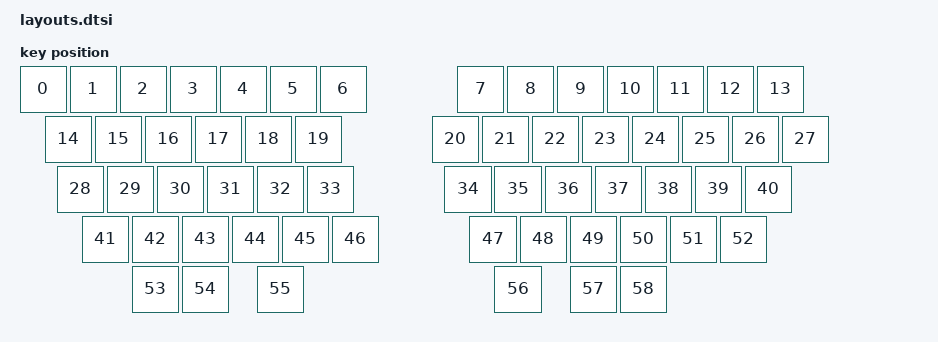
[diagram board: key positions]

#include <physical_layouts.dtsi>
/ {
    physical_layout0: physical_layout0 {
        compatible = "zmk,physical-layout";
        display-name = "Layout";
        keys
            = <&key_physical_attrs 100 100 (-50) 0 0 0 0>
			,<&key_physical_attrs 100 100 50 0 0 0 0>
			,<&key_physical_attrs 100 100 150 0 0 0 0>
			,<&key_physical_attrs 100 100 250 0 0 0 0>
			,<&key_physical_attrs 100 100 350 0 0 0 0>
			,<&key_physical_attrs 100 100 450 0 0 0 0>
			,<&key_physical_attrs 100 100 550 0 0 0 0>
			,<&key_physical_attrs 100 100 825 0 0 0 0>
			,<&key_physical_attrs 100 100 925 0 0 0 0>
			,<&key_physical_attrs 100 100 1025 0 0 0 0>
			,<&key_physical_attrs 100 100 1125 0 0 0 0>
			,<&key_physical_attrs 100 100 1225 0 0 0 0>
			,<&key_physical_attrs 100 100 1325 0 0 0 0>
			,<&key_physical_attrs 100 100 1425 0 0 0 0>
			,<&key_physical_attrs 100 100 0 100 0 0 0>
			,<&key_physical_attrs 100 100 100 100 0 0 0>
			,<&key_physical_attrs 100 100 200 100 0 0 0>
			,<&key_physical_attrs 100 100 300 100 0 0 0>
			,<&key_physical_attrs 100 100 400 100 0 0 0>
			,<&key_physical_attrs 100 100 500 100 0 0 0>
			,<&key_physical_attrs 100 100 775 100 0 0 0>
			,<&key_physical_attrs 100 100 875 100 0 0 0>
			,<&key_physical_attrs 100 100 975 100 0 0 0>
			,<&key_physical_attrs 100 100 1075 100 0 0 0>
			,<&key_physical_attrs 100 100 1175 100 0 0 0>
			,<&key_physical_attrs 100 100 1275 100 0 0 0>
			,<&key_physical_attrs 100 100 1375 100 0 0 0>
			,<&key_physical_attrs 100 100 1475 100 0 0 0>
			,<&key_physical_attrs 100 100 25 200 0 0 0>
			,<&key_physical_attrs 100 100 125 200 0 0 0>
			,<&key_physical_attrs 100 100 225 200 0 0 0>
			,<&key_physical_attrs 100 100 325 200 0 0 0>
			,<&key_physical_attrs 100 100 425 200 0 0 0>
			,<&key_physical_attrs 100 100 525 200 0 0 0>
			,<&key_physical_attrs 100 100 800 200 0 0 0>
			,<&key_physical_attrs 100 100 900 200 0 0 0>
			,<&key_physical_attrs 100 100 1000 200 0 0 0>
			,<&key_physical_attrs 100 100 1100 200 0 0 0>
			,<&key_physical_attrs 100 100 1200 200 0 0 0>
			,<&key_physical_attrs 100 100 1300 200 0 0 0>
			,<&key_physical_attrs 100 100 1400 200 0 0 0>
			,<&key_physical_attrs 100 100 75 300 0 0 0>
			,<&key_physical_attrs 100 100 175 300 0 0 0>
			,<&key_physical_attrs 100 100 275 300 0 0 0>
			,<&key_physical_attrs 100 100 375 300 0 0 0>
			,<&key_physical_attrs 100 100 475 300 0 0 0>
			,<&key_physical_attrs 100 100 575 300 0 0 0>
			,<&key_physical_attrs 100 100 850 300 0 0 0>
			,<&key_physical_attrs 100 100 950 300 0 0 0>
			,<&key_physical_attrs 100 100 1050 300 0 0 0>
			,<&key_physical_attrs 100 100 1150 300 0 0 0>
			,<&key_physical_attrs 100 100 1250 300 0 0 0>
			,<&key_physical_attrs 100 100 1350 300 0 0 0>
			,<&key_physical_attrs 100 100 175 400 0 0 0>
			,<&key_physical_attrs 100 100 275 400 0 0 0>
			,<&key_physical_attrs 100 100 425 400 0 0 0>
			,<&key_physical_attrs 100 100 900 400 0 0 0>
			,<&key_physical_attrs 100 100 1050 400 0 0 0>
			,<&key_physical_attrs 100 100 1150 400 0 0 0>
            ;
    };
};
    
